# N32H7xx register map
Vendor: Nationstech Ltd.; File version: 1.0
Registers are 32-bit, read-write, reset 0x0 unless marked. A register's access mark holds for its fields unless they carry their own. Offsets are from the block's base; [hi:lo] are bit positions; {n}, {i} and the like mark numbered series.

## FDCAN1 — Flexible Datarate Controller Area Network
Base 0x40000000
Same registers: FDCAN2 0x40000400, FDCAN5 0x40000800, FDCAN6 0x40000C00, FDCAN3 0x400D0000, FDCAN4 0x400D0400, FDCAN7 0x400D0800, FDCAN8 0x400D0C00
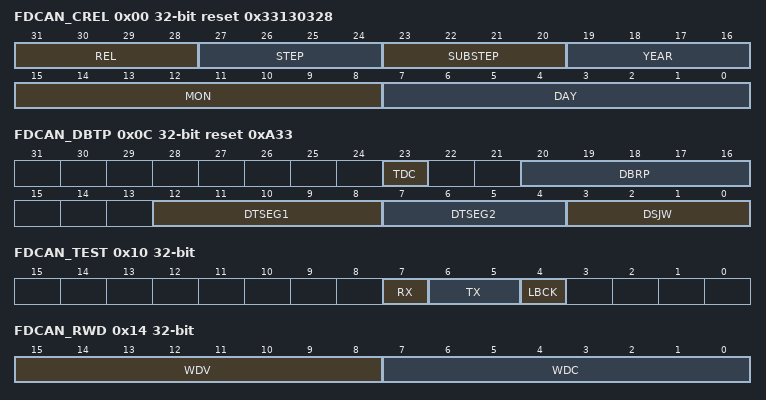
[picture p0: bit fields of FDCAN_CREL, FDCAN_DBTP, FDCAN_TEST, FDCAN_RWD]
0x00 FDCAN_CREL ro reset 0x33130328 — FDCAN Core Release Register
  [31:28] REL — Core release
  [27:24] STEP — Step of Core release
  [23:20] SUBSTEP — Sub-step of Core release
  [19:16] YEAR — Timestamp Year
  [15:8] MON — Timestamp Month
  [7:0] DAY — Timestamp Day
0x04 FDCAN_ENDN ro reset 0x87654321 — FDCAN Endian register
  [31:0] ETV — Endiannes Test value
0x0C FDCAN_DBTP reset 0xA33 — FDCAN Data Bit Timing and Prescaler Register
  [23] TDC — Transceiver Delay Compensation
  [20:16] DBRP — Data BIt Rate Prescaler
  [12:8] DTSEG1 — Data time segment after sample point
  [7:4] DTSEG2 — Data time segment after sample point
  [3:0] DSJW — Synchronization Jump Width
0x10 FDCAN_TEST
  [7] RX ro — Receive pin
  [6:5] TX — Control of transmit pin
  [4] LBCK — Loop Back mode
0x14 FDCAN_RWD — FDCAN RAM watchdog registe
  [15:8] WDV ro — Watchdog value
  [7:0] WDC — Watchdog configuration
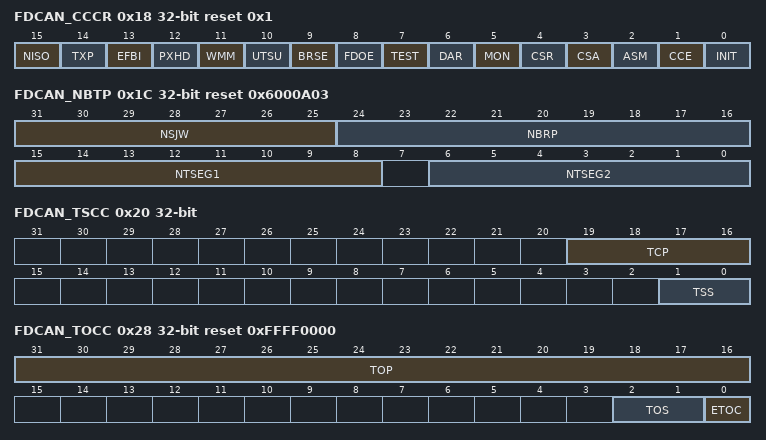
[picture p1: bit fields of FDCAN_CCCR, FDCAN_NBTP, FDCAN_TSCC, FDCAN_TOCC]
0x18 FDCAN_CCCR reset 0x1 — FDCAN CC control registe
  [15] NISO — Non ISO operation
  [14] TXP — Transmit Pause
  [13] EFBI — Edge Filtering during Bus Integration
  [12] PXHD — Protocol Exception Handling Disable
  [11] WMM — Wide Message Marker
  [10] UTSU — Use Timestamping Unit
  [9] BRSE — Bit Rate Switch Enable
  [8] FDOE — FD Operation Enable
  [7] TEST — Test Mode Enable
  [6] DAR — Disable Automatic Retransmission
  [5] MON — Bus Monitoring Mode
  [4] CSR — Clock Stop Request
  [3] CSA — Clock Stop Acknowledge
  [2] ASM — ASM Restricted Operation Mode
  [1] CCE — Configuration change enable
  [0] INIT — Initialization
0x1C FDCAN_NBTP reset 0x6000A03 — FDCAN nominal bit timing and prescaler register
  [31:25] NSJW — Nominal (re)synchronization jump width
  [24:16] NBRP — Bitrate prescaler
  [15:8] NTSEG1 — Nominal time segment before sample point
  [6:0] NTSEG2 — Nominal time segment after sample point
0x20 FDCAN_TSCC — FDCAN timestamp counter configuration register
  [19:16] TCP — Timestamp counter prescaler
  [1:0] TSS — Timestamp select
0x24 FDCAN_TSCV — FDCAN timestamp counter value register
  [15:0] TSC — Timestamp counter
0x28 FDCAN_TOCC reset 0xFFFF0000 — FDCAN timeout counter configuration register
  [31:16] TOP — Timeout period
  [2:1] TOS — Timeout select
  [0] ETOC — Enable timeout counter
0x2C FDCAN_TOCV reset 0xFFFF — FDCAN timeout counter value register
  [15:0] TOC — Timeout counter
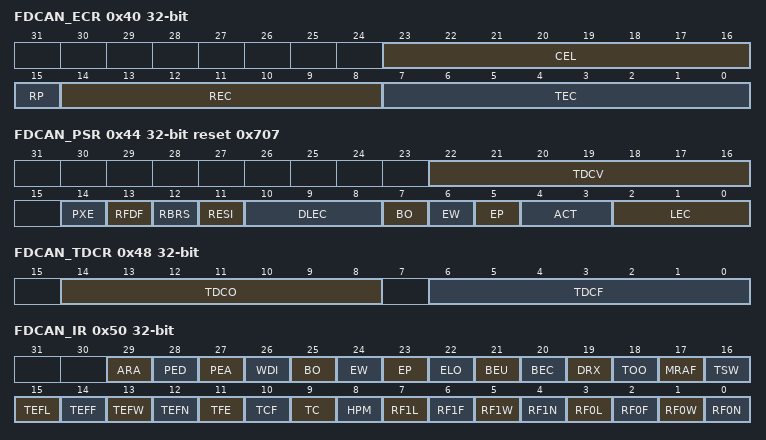
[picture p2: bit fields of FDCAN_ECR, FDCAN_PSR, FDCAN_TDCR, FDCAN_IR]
0x40 FDCAN_ECR ro — FDCAN error counter register
  [23:16] CEL — CAN error logging
  [15] RP — Receive error passive
  [14:8] REC — Receive error counter
  [7:0] TEC — Transmit error counter
0x44 FDCAN_PSR ro reset 0x707 — FDCAN protocol status register
  [22:16] TDCV — Transmitter Delay Compensation value
  [14] PXE — Protocol exception event
  [13] RFDF — Received FDCAN message
  [12] RBRS — BRS flag of last received FDCAN message
  [11] RESI — ESI flag of last received FDCAN message
  [10:8] DLEC — Data Last error code
  [7] BO — Bus_Off status
  [6] EW — Warning status
  [5] EP — Error Passive
  [4:3] ACT — Activity
  [2:0] LEC — Last error code
0x48 FDCAN_TDCR — FDCAN transmitter delay compensation register
  [14:8] TDCO — Transmitter delay compensation offset
  [6:0] TDCF — Transmitter delay compensation filter window length
0x50 FDCAN_IR — FDCAN interrupt register
  [29] ARA — Access to Reserved address
  [28] PED — Protocol error in data phase
  [27] PEA — Protocol error in Arbitration phase
  [26] WDI — Watchdog interrupt
  [25] BO — Bus_Off status
  [24] EW — Warning status
  [23] EP — Error Passive
  [22] ELO — Error logging Overflow
  [21] BEU — Bit Error Uncorrected
  [20] BEC — Bit Error Corrected
  [19] DRX — Message stored to dedicated Rx buffer
  [18] TOO — Timeout occurred
  [17] MRAF — Message RAM Access Failure
  [16] TSW — Timestamp wraparound
  [15] TEFL — Tx event FIFO element Lost
  [14] TEFF — Tx event FIFO Full
  [13] TEFW — Tx event FIFO Watermark Reached
  [12] TEFN — Tx event FIFO New Entry
  [11] TFE — Tx FIFO Empty
  [10] TCF — Transmission cancellation finished
  [9] TC — Transmission Completed
  [8] HPM — High priority message
  [7] RF1L — Rx FIFO 1 message Lost
  [6] RF1F — Rx FIFO 1 Full
  [5] RF1W — Rx FIFO 1 Watermark Reached
  [4] RF1N — Rx FIFO 1 new message
  [3] RF0L — Rx FIFO 0 message Lost
  [2] RF0F — Rx FIFO 0 Full
  [1] RF0W — Rx FIFO 0 Watermark Reached
  [0] RF0N — Rx FIFO 0 New message
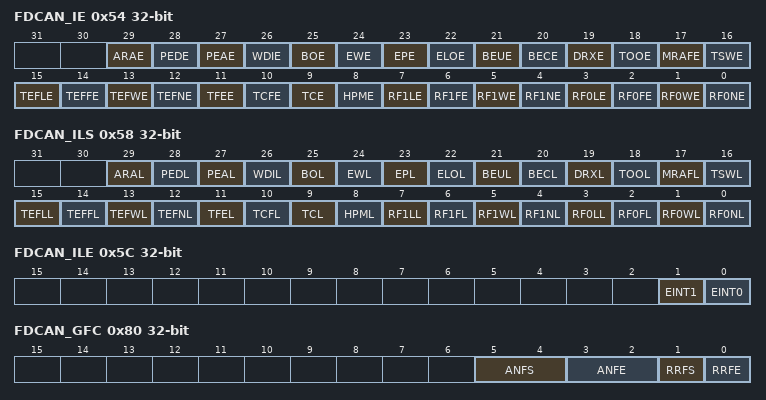
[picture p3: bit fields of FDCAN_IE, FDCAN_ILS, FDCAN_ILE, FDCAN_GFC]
0x54 FDCAN_IE — FDCAN interrupt enable register
  [29] ARAE — Access to Reserved address enable
  [28] PEDE — Protocol error in data phase enable
  [27] PEAE — Protocol error in Arbitration phase enable
  [26] WDIE — Watchdog interrupt enable
  [25] BOE — Bus_Off status interrupt enable
  [24] EWE — Warning status interrupt enable
  [23] EPE — Error passive interrupt enable
  [22] ELOE — Error logging overflow interrupt enable
  [21] BEUE — Bit Error Uncorrected interrupt enable
  [20] BECE — Bit Error Corrected interrupt enable
  [19] DRXE — Message stored to dedicated Rx buffer interrupt enable
  [18] TOOE — Timeout occurred interrupt enable
  [17] MRAFE — Message RAM access failure interrupt enable
  [16] TSWE — Timestamp wraparound interrupt enable
  [15] TEFLE — Tx event FIFO element lost interrupt enable
  [14] TEFFE — Tx event FIFO full interrupt enable
  [13] TEFWE — Tx event FIFO watermark reached interrupt enable
  [12] TEFNE — Tx event FIFO new entry interrupt enable
  [11] TFEE — Tx FIFO empty interrupt enable
  [10] TCFE — Transmission cancellation finished interrupt enable
  [9] TCE — Transmission completed interrupt enable
  [8] HPME — High priority message interrupt enable
  [7] RF1LE — Rx FIFO 1 message lost interrupt enable
  [6] RF1FE — Rx FIFO 1 full interrupt enable
  [5] RF1WE — Rx FIFO 1 watermark reached interrupt enable
  [4] RF1NE — Rx FIFO 1 new message interrupt enable
  [3] RF0LE — Rx FIFO 0 message lost interrupt enable
  [2] RF0FE — Rx FIFO 0 full interrupt enable
  [1] RF0WE — Rx FIFO 0 watermark reached interrupt enable
  [0] RF0NE — Rx FIFO 0 new message interrupt enable
0x58 FDCAN_ILS — FDCAN interrupt line select register
  [29] ARAL — Access to reserved address line
  [28] PEDL — Protocol error in data phase line
  [27] PEAL — Protocol error in arbitration phase line
  [26] WDIL — Watchdog interrupt Line
  [25] BOL — Bus_Off status intrrupt Line
  [24] EWL — Warning status interrupt Line
  [23] EPL — Error passive interrupt line
  [22] ELOL — Error logging overflow interrupt line
  [21] BEUL — Bit Error Uncorrected interrupt line
  [20] BECL — Bit Error Corrected interrupt line
  [19] DRXL — Message stored to dedicated Rx buffer interrupt line
  [18] TOOL — Timeout occurred interrupt Line
  [17] MRAFL — Message RAM access failure interrupt line
  [16] TSWL — Timestamp wraparound interrupt line
  [15] TEFLL — Tx event FIFO element Lost interrupt line
  [14] TEFFL — Tx event FIFO full interrupt line
  [13] TEFWL — Tx event FIFO watermark reached interrupt line
  [12] TEFNL — Tx event FIFO new entry interrupt line
  [11] TFEL — Tx FIFO empty interrupt Line
  [10] TCFL — Transmission cancellation finished interrupt line
  [9] TCL — Transmission completed interrupt line
  [8] HPML — High priority message interrupt line
  [7] RF1LL — Rx FIFO 1 message lost interrupt line
  [6] RF1FL — Rx FIFO 1 full interrupt line
  [5] RF1WL — Rx FIFO 1 watermark reached interrupt line
  [4] RF1NL — Rx FIFO 1 new message interrupt line
  [3] RF0LL — Rx FIFO 0 message lost interrupt line
  [2] RF0FL — Rx FIFO 0 full interrupt line
  [1] RF0WL — Rx FIFO 0 watermark reached interrupt line
  [0] RF0NL — Rx FIFO 0 new message interrupt line
0x5C FDCAN_ILE — FDCAN interrupt line enable register
  [1] EINT1 — Enable interrupt Line 1
  [0] EINT0 — Enable interrupt Line 0
0x80 FDCAN_GFC — FDCAN global filter configuration register
  [5:4] ANFS — Accept non-matching frames standard
  [3:2] ANFE — Accept non-matching frames extended
  [1] RRFS — Reject remote frames standard
  [0] RRFE — Reject remote frames extended
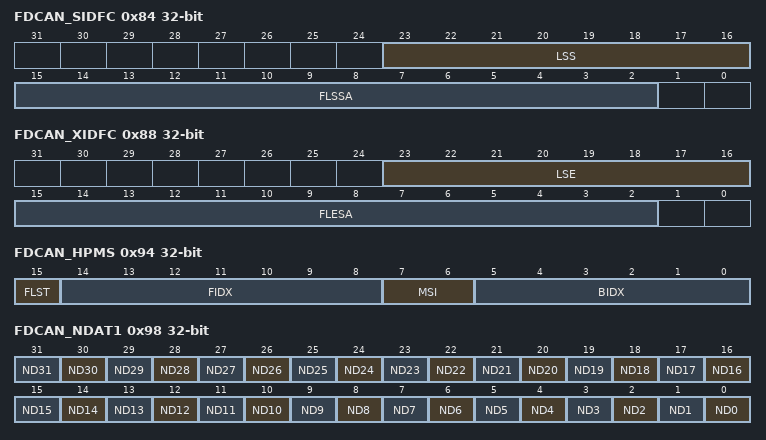
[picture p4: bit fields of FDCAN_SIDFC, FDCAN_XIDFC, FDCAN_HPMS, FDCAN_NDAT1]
0x84 FDCAN_SIDFC — FDCAN standard ID filter configuration register
  [23:16] LSS — List size standard
  [15:2] FLSSA — Filter list standard start address
0x88 FDCAN_XIDFC — FDCAN extended ID filter configuration register
  [23:16] LSE — List size extended
  [15:2] FLESA — Filter list extended start address
0x90 FDCAN_XIDAM reset 0x1FFFFFFF — FDCAN extended ID and mask register
  [28:0] EIDM — Extended ID Mask
0x94 FDCAN_HPMS ro — FDCAN high priority message status register
  [15] FLST — Filter list
  [14:8] FIDX — Filter index
  [7:6] MSI — Message Storage Indicator
  [5:0] BIDX — Buffer index
0x98 FDCAN_NDAT1 — FDCAN new data register 1
  [n] ND{n} (n=0..31) — New data {n}
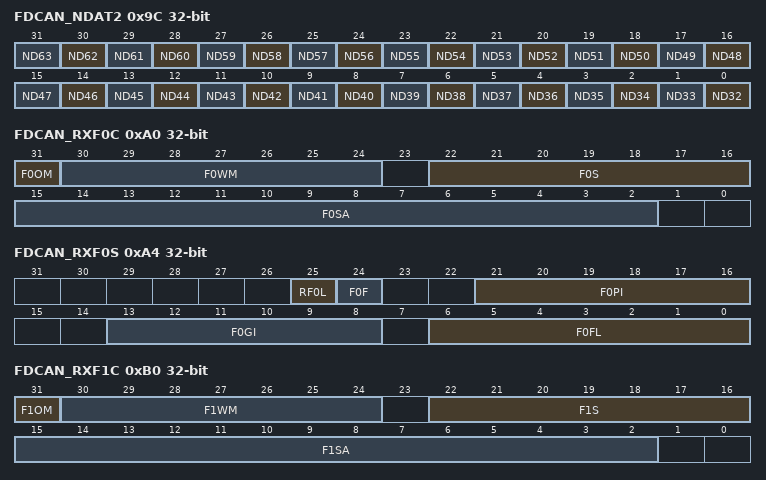
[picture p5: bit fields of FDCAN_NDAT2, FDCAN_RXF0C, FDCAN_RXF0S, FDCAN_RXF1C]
0x9C FDCAN_NDAT2 — FDCAN new data register 2
  [n-32] ND{n} (n=32..63) — New data {n}
0xA0 FDCAN_RXF0C — FDCAN Rx FIFO 0 configuration register
  [31] F0OM — FIFO 0 operation mode
  [30:24] F0WM — FIFO 0 Watermark
  [22:16] F0S — Rx FIFO 0 size
  [15:2] F0SA — Rx FIFO 0 start address
0xA4 FDCAN_RXF0S ro — FDCAN Rx FIFO 0 status register
  [25] RF0L — Rx FIFO 0 message Lost
  [24] F0F — Rx FIFO 0 Full
  [21:16] F0PI — Rx FIFO 0 put index
  [13:8] F0GI — Rx FIFO 0 get index
  [6:0] F0FL — Rx FIFO 0 fill level
0xA8 FDCAN_RXF0A — FDCAN Rx FIFO 0 acknowledge register
  [5:0] F0AI — Rx FIFO 0 acknowledge index
0xAC FDCAN_RXBC — FDCAN Rx buffer configuration register
  [15:2] RBSA — Rx buffer start address
0xB0 FDCAN_RXF1C — FDCAN Rx FIFO 1 configuration register
  [31] F1OM — FIFO 1Operation mode
  [30:24] F1WM — Rx FIFO 1 Watermark
  [22:16] F1S — Rx FIFO 1 size
  [15:2] F1SA — Rx FIFO 1 start address
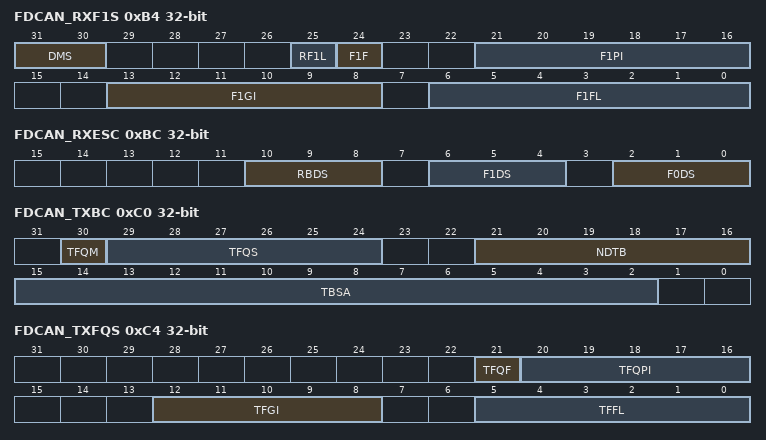
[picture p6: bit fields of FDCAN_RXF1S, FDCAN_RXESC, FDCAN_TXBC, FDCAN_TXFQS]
0xB4 FDCAN_RXF1S ro — FDCAN Rx FIFO 1 status register
  [31:30] DMS — Debug message status
  [25] RF1L — Rx FIFO 1 message Lost
  [24] F1F — Rx FIFO 1 Full
  [21:16] F1PI — Rx FIFO 1 put index
  [13:8] F1GI — Rx FIFO 1 get index
  [6:0] F1FL — Rx FIFO 1 fill level
0xB8 FDCAN_RXF1A — FDCAN Rx FIFO 1 acknowledge register
  [5:0] F1AI — Rx FIFO 1 acknowledge index
0xBC FDCAN_RXESC — FDCAN Rx buffer element size configuration register
  [10:8] RBDS — Rx buffer data Field size
  [6:4] F1DS — Rx FIFO 1 data Field size
  [2:0] F0DS — Rx FIFO 0 data Field size
0xC0 FDCAN_TXBC — FDCAN Tx buffer configuration register
  [30] TFQM — Tx FIFO/queue mode
  [29:24] TFQS — Transmit FIFO/queue size
  [21:16] NDTB — Number of dedicated transmit buffers
  [15:2] TBSA — Tx buffers start address
0xC4 FDCAN_TXFQS ro — FDCAN Tx FIFO/queue status register
  [21] TFQF — Tx FIFO/queue Full
  [20:16] TFQPI — Tx FIFO/queue put index
  [12:8] TFGI — Tx FIFO/queue get index
  [5:0] TFFL — Tx FIFO free level
0xC8 FDCAN_TXESC — FDCAN Tx buffer element size configuration register
  [2:0] TBDS — Tx buffer data Field size
0xCC FDCAN_TXBRP ro — FDCAN Tx buffer request pending register
  [31:0] TRP — Transmission request pending
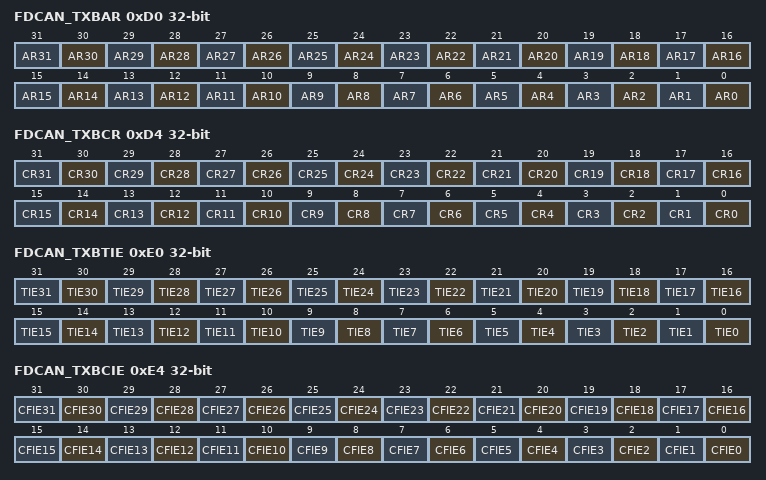
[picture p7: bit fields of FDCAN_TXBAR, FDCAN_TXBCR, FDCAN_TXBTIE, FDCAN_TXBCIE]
0xD0 FDCAN_TXBAR — FDCAN Tx buffer add request register
  [n] AR{n} (n=0..31) — Add request {n}
0xD4 FDCAN_TXBCR — FDCAN Tx buffer cancellation request register
  [n] CR{n} (n=0..31) — Cancellation request {n}
0xD8 FDCAN_TXBTO ro — FDCAN Tx buffer transmission occurred register
  [31:0] TO — Transmission occurred
0xDC FDCAN_TXBCF ro — FDCAN Tx buffer cancellation finished register
  [31:0] CF — Cancellation finished
0xE0 FDCAN_TXBTIE — FDCAN Tx buffer transmission interrupt enable register
  [n] TIE{n} (n=0..31) — Tx buffer {n} Transmission interrupt enable
0xE4 FDCAN_TXBCIE — FDCAN Tx buffer cancellation finished interrupt enable register
  [n] CFIE{n} (n=0..31) — Tx buffer {n} Cancellation finished interrupt enable
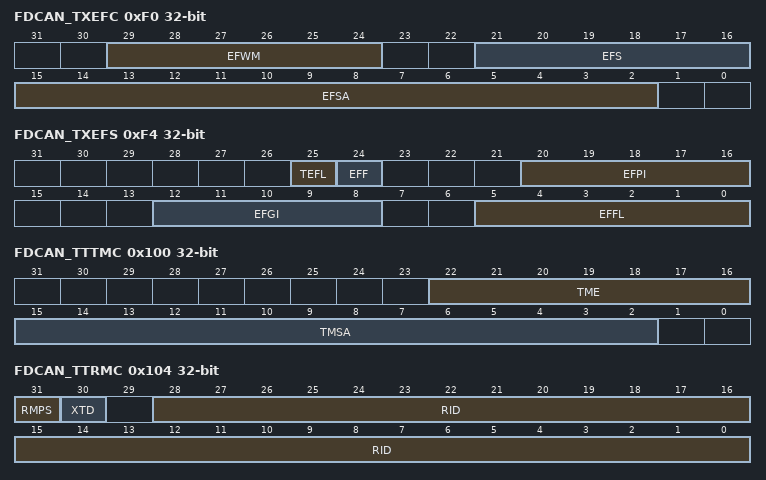
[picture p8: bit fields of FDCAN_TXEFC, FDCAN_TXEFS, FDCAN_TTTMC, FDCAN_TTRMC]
0xF0 FDCAN_TXEFC — FDCAN Tx event FIFO configuration register
  [29:24] EFWM — Event FIFO Watermark
  [21:16] EFS — Event FIFO size
  [15:2] EFSA — Event FIFO start address
0xF4 FDCAN_TXEFS ro — FDCAN Tx event FIFO status register
  [25] TEFL — Tx event FIFO element Lost
  [24] EFF — Event FIFO Full
  [20:16] EFPI — Event FIFO put index
  [12:8] EFGI — Event FIFO get index
  [5:0] EFFL — Event FIFO fill level
0xF8 FDCAN_TXEFA — FDCAN Tx event FIFO acknowledge register
  [4:0] EFAI — Event FIFO acknowledge index
0x100 FDCAN_TTTMC — nan
  [22:16] TME, [15:2] TMSA
0x104 FDCAN_TTRMC — nan
  [31] RMPS, [30] XTD, [28:0] RID
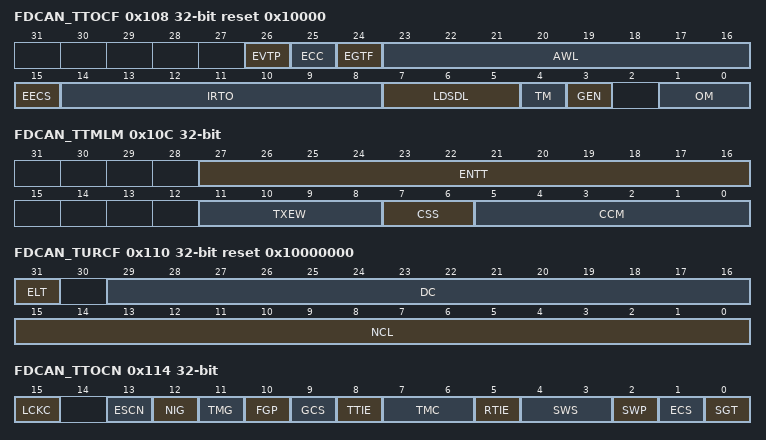
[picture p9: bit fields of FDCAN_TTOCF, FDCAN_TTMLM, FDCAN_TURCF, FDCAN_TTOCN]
0x108 FDCAN_TTOCF reset 0x10000 — nan
  [26] EVTP, [25] ECC, [24] EGTF, [23:16] AWL, [15] EECS, [14:8] IRTO, [7:5] LDSDL, [4] TM, [3] GEN, [1:0] OM
0x10C FDCAN_TTMLM — nan
  [27:16] ENTT, [11:8] TXEW, [7:6] CSS, [5:0] CCM
0x110 FDCAN_TURCF reset 0x10000000 — nan
  [31] ELT, [29:16] DC, [15:0] NCL
0x114 FDCAN_TTOCN — nan
  [15] LCKC, [13] ESCN, [12] NIG, [11] TMG, [10] FGP, [9] GCS, [8] TTIE, [7:6] TMC, [5] RTIE, [4:3] SWS, [2] SWP, [1] ECS, [0] SGT
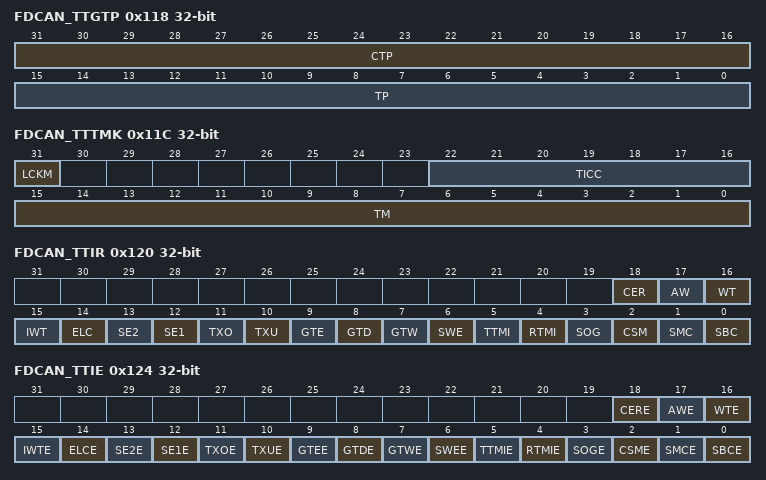
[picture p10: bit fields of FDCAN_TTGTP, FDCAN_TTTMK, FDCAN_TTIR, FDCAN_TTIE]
0x118 FDCAN_TTGTP — nan
  [31:16] CTP, [15:0] TP
0x11C FDCAN_TTTMK — nan
  [31] LCKM, [22:16] TICC, [15:0] TM
0x120 FDCAN_TTIR — nan
  [18] CER, [17] AW, [16] WT, [15] IWT, [14] ELC, [13] SE2, [12] SE1, [11] TXO, [10] TXU, [9] GTE, [8] GTD, [7] GTW, [6] SWE, [5] TTMI, [4] RTMI, [3] SOG, [2] CSM, [1] SMC, [0] SBC
0x124 FDCAN_TTIE — nan
  [18] CERE, [17] AWE, [16] WTE, [15] IWTE, [14] ELCE, [13] SE2E, [12] SE1E, [11] TXOE, [10] TXUE, [9] GTEE, [8] GTDE, [7] GTWE, [6] SWEE, [5] TTMIE, [4] RTMIE, [3] SOGE, [2] CSME, [1] SMCE, [0] SBCE
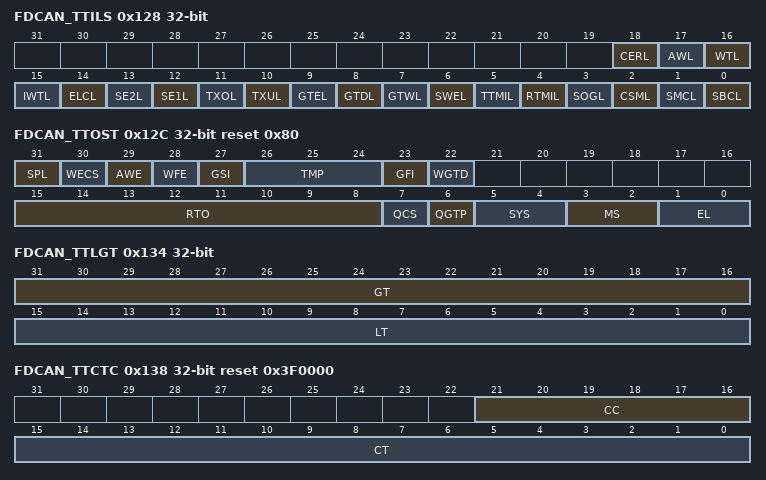
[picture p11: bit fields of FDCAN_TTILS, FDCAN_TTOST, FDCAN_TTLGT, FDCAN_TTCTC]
0x128 FDCAN_TTILS — nan
  [18] CERL, [17] AWL, [16] WTL, [15] IWTL, [14] ELCL, [13] SE2L, [12] SE1L, [11] TXOL, [10] TXUL, [9] GTEL, [8] GTDL, [7] GTWL, [6] SWEL, [5] TTMIL, [4] RTMIL, [3] SOGL, [2] CSML, [1] SMCL, [0] SBCL
0x12C FDCAN_TTOST reset 0x80 — nan
  [31] SPL, [30] WECS, [29] AWE, [28] WFE, [27] GSI, [26:24] TMP, [23] GFI, [22] WGTD, [15:8] RTO, [7] QCS, [6] QGTP, [5:4] SYS, [3:2] MS, [1:0] EL
0x130 FDCAN_TURNA reset 0x10000 — nan
  [17:0] NAV
0x134 FDCAN_TTLGT — nan
  [31:16] GT, [15:0] LT
0x138 FDCAN_TTCTC reset 0x3F0000 — nan
  [21:16] CC, [15:0] CT
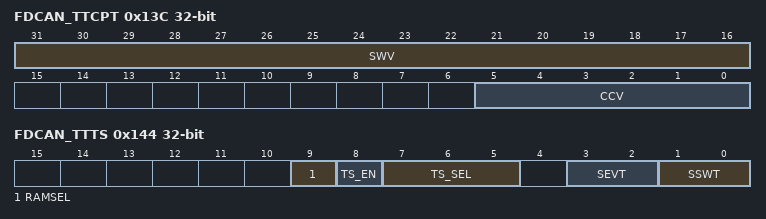
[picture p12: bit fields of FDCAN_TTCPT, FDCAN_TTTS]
0x13C FDCAN_TTCPT — nan
  [31:16] SWV, [5:0] CCV
0x140 FDCAN_TTCSM — nan
  [15:0] CSM
0x144 FDCAN_TTTS — FDCAN external signal select register
  [9] RAMSEL — Message RAM select
  [8] TS_EN — External timestamp vector enable
  [7:5] TS_SEL — Select external timestamp’s clock divided
  [3:2] SEVT — Select SEVT
  [1:0] SSWT — Select SSWT
